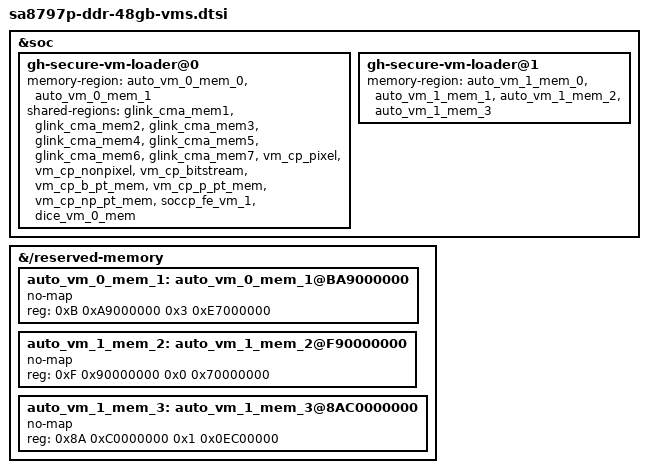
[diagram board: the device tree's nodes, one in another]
// SPDX-License-Identifier: BSD-3-Clause
/*
 * Copyright (c) Qualcomm Technologies, Inc. and/or its subsidiaries.
 */

#include "oot-dt-bindings/qcom-shmem-sa8797p.h"

&soc {
	gh-secure-vm-loader@0 {
		memory-region = <&auto_vm_0_mem_0 &auto_vm_0_mem_1>;
		shared-regions = <&glink_cma_mem1
				&glink_cma_mem2
				&glink_cma_mem3
				&glink_cma_mem4
				&glink_cma_mem5
				&glink_cma_mem6
				&glink_cma_mem7
				&vm_cp_pixel
				&vm_cp_nonpixel
				&vm_cp_bitstream
				&vm_cp_b_pt_mem
				&vm_cp_p_pt_mem
				&vm_cp_np_pt_mem
				&soccp_fe_vm_1
				&dice_vm_0_mem>;
	};

	gh-secure-vm-loader@1 {
		memory-region = <&auto_vm_1_mem_0 &auto_vm_1_mem_1 &auto_vm_1_mem_2 &auto_vm_1_mem_3>;
	};
};

&{/reserved-memory} {

	auto_vm_0_mem_1: auto_vm_0_mem_1@BA9000000 {
		no-map;
		reg = <0xB 0xA9000000 0x3 0xE7000000>; /* 15984MB */
	};

	auto_vm_1_mem_2: auto_vm_1_mem_2@F90000000 {
		no-map;
		reg = <0xF 0x90000000 0x0 0x70000000>; /*1792MB*/
	};

	auto_vm_1_mem_3: auto_vm_1_mem_3@8AC0000000 {
		no-map;
		reg = <0x8A 0xC0000000 0x1 0x0EC00000>; /*4332MB*/
	};
};
